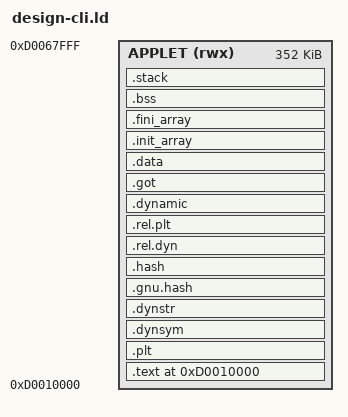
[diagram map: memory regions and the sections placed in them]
/* Generated by cgarm-build; edit the options, not this file. */
/* SIDBOX GUI V2 EXPERIMENTAL PIE linker template (NOT for games or legacy apps).
 * The packer extracts PT_LOAD and R_ARM_RELATIVE; the firmware chooses runtime SDRAM.
 * IDE modifies the 3 settings below on each project build.
 */
_v2_app_limit   = 0x58000;  /* 128 KiB default; firmware V2 test loader caps at 512 KiB */
_v2_stack_bytes = 0x8000;   /* Stage 6C private PSP for GUI/timer callbacks, entry still on MSP */
_v2_heap_bytes  = 0x20000;   /* uninitialised additional RAM; bounded _sbrk */

/* Link-time virtual SDRAM base needed only for relative addresses in ELF.
 * Actual load base is selected by CoderGirl; the packer preserves relocations. */
_v2_link_base = 0xD0010000;
ENTRY(applet_entry)
MEMORY {
    APPLET (rwx) : ORIGIN = _v2_link_base, LENGTH = _v2_app_limit
}
_appstart = ORIGIN(APPLET);
PROVIDE(__app_start = _appstart);
SECTIONS {
    . = ORIGIN(APPLET);
    .text : {
        . = ALIGN(4);
        KEEP(*(.text.applet_entry))
        *(.text*)
        *(.rodata*)
    } > APPLET

    /* These are part of the linked PIE image. Never discard .rel.dyn. */
    .plt : { *(.plt*) } > APPLET
    .dynsym : { *(.dynsym*) } > APPLET
    .dynstr : { *(.dynstr*) } > APPLET
    .gnu.hash : { *(.gnu.hash*) } > APPLET
    .hash : { *(.hash*) } > APPLET
    .rel.dyn : { *(.rel.dyn) } > APPLET
    .rel.plt : { *(.rel.plt) } > APPLET
    .dynamic : { *(.dynamic) } > APPLET
    .got : { *(.got*) } > APPLET
    .data : { . = ALIGN(4); *(.data*) } > APPLET
    .init_array : { KEEP(*(.init_array*)) } > APPLET
    .fini_array : { KEEP(*(.fini_array*)) } > APPLET
    .bss (NOLOAD) : {
        . = ALIGN(8);
        __bss_start__ = .;
        *(.bss*) *(COMMON)
        . = ALIGN(8);
        __bss_end__ = .;
    } > APPLET
    .stack (NOLOAD) : {
        . = ALIGN(8);
        __stack_start__ = .;
        . = . + _v2_stack_bytes;
        . = ALIGN(8);
        __stack_end__ = .;
    } > APPLET
    __app_end = __stack_end__;
    _end = __app_end;
    PROVIDE(__v2_heap_start__ = __stack_end__);
    PROVIDE(__app_end_clear = __stack_end__);
    PROVIDE(_estack = __stack_end__);
}
ASSERT((_v2_app_limit & 31) == 0, "V2 RAM allowance must be 32-byte aligned");
ASSERT(__stack_end__ + _v2_heap_bytes <= ORIGIN(APPLET) + LENGTH(APPLET),
       "V2 code + BSS + reserved stack + heap exceed applet allowance");
